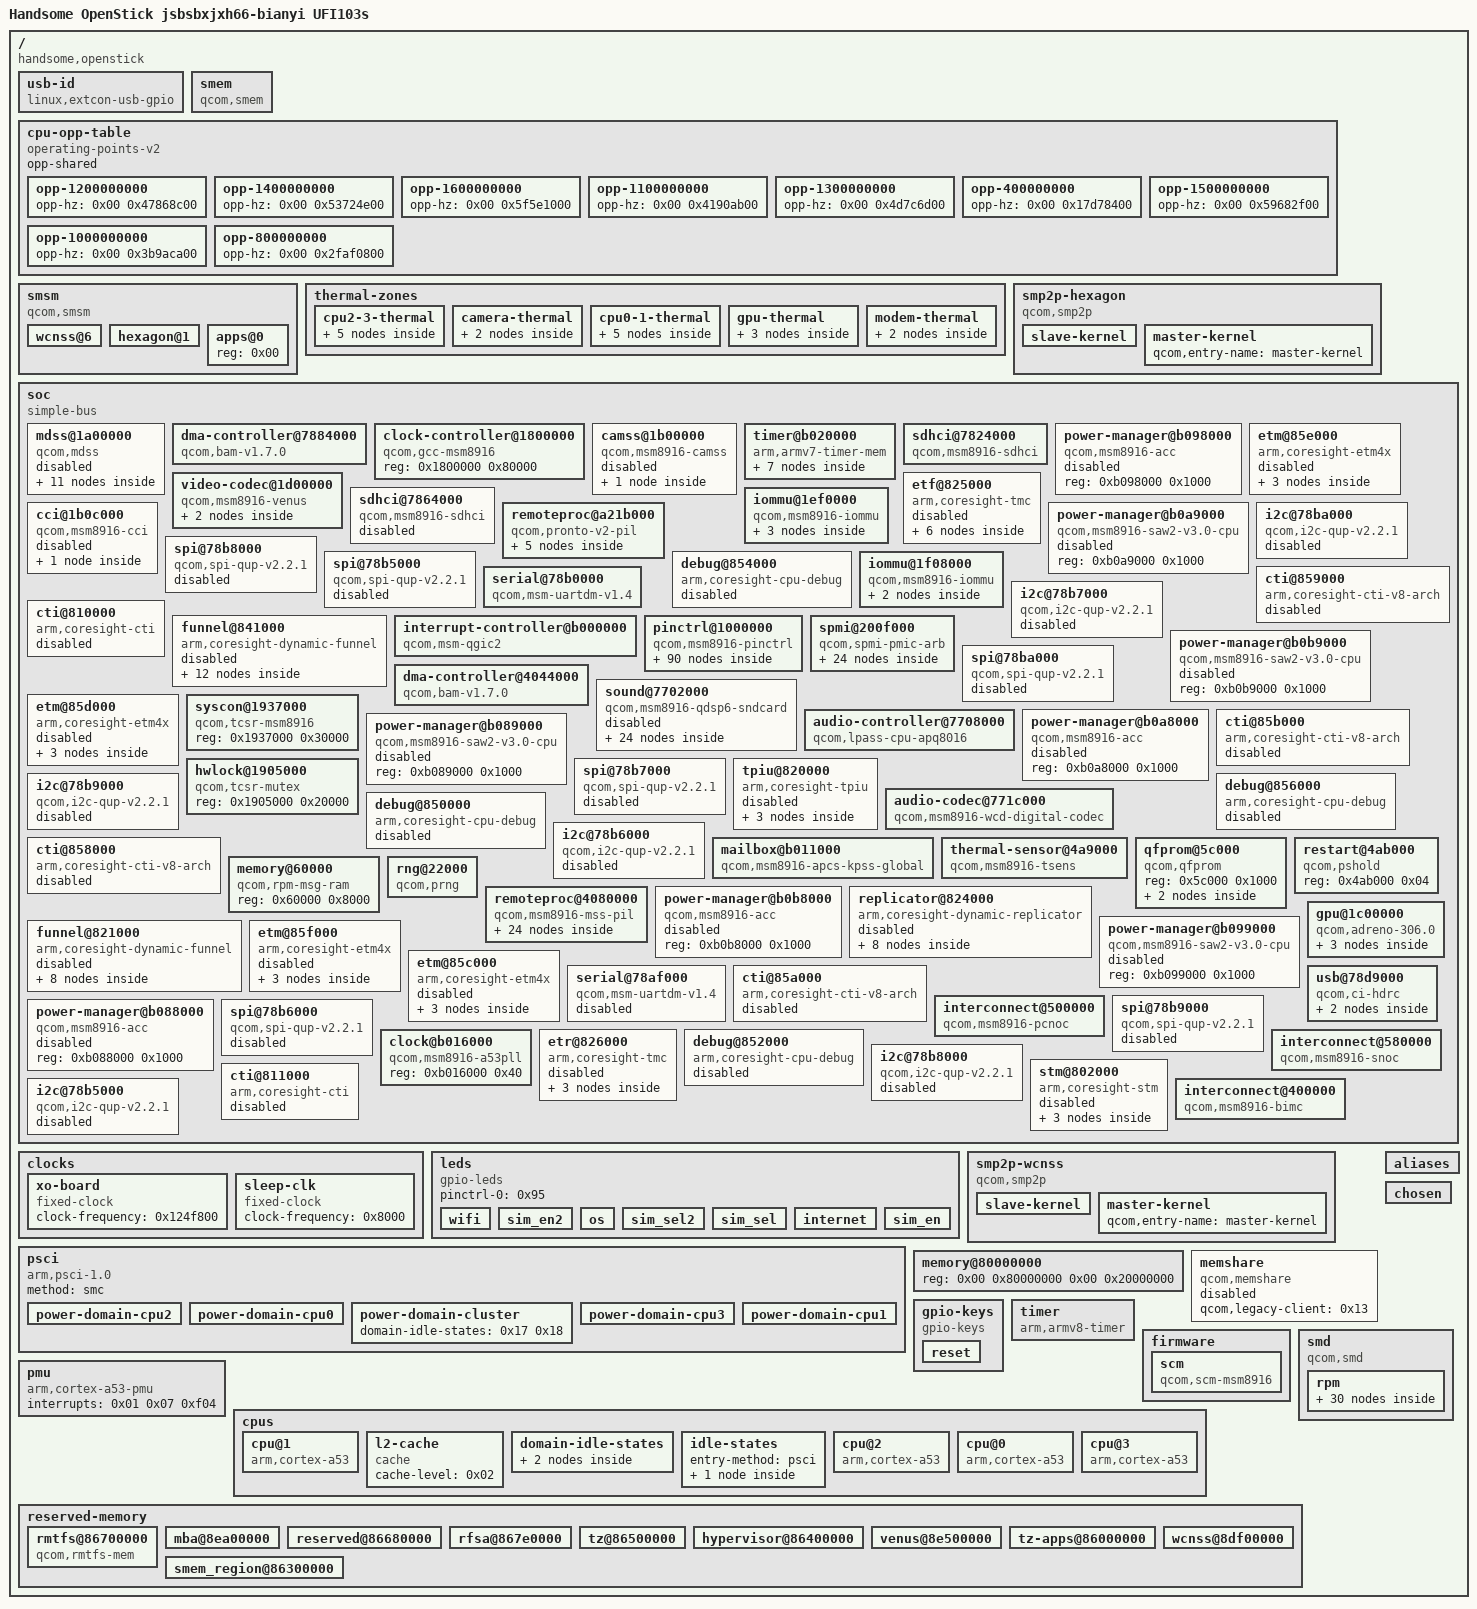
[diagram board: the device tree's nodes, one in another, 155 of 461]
/dts-v1/;

/ {
	#address-cells = <0x02>;
	model = "Handsome OpenStick  jsbsbxjxh66-bianyi UFI103s";
	#size-cells = <0x02>;
	interrupt-parent = <0x01>;
	compatible = "handsome,openstick\0qcom,msm8916";

	usb-id {
		pinctrl-names = "default";
		id-gpio = <0x3e 0x6e 0x00>;
		pinctrl-0 = <0x93>;
		compatible = "linux,extcon-usb-gpio";
		phandle = <0x87>;
	};

	smem {
		memory-region = <0x1c>;
		compatible = "qcom,smem";
		qcom,rpm-msg-ram = <0x1d>;
		hwlocks = <0x1e 0x03>;
	};

	cpu-opp-table {
		opp-shared;
		compatible = "operating-points-v2";
		phandle = <0x04>;

		opp-1200000000 {
			opp-hz = <0x00 0x47868c00>;
		};

		opp-1400000000 {
			opp-hz = <0x00 0x53724e00>;
		};

		opp-1600000000 {
			opp-hz = <0x00 0x5f5e1000>;
		};

		opp-1100000000 {
			opp-hz = <0x00 0x4190ab00>;
		};

		opp-1300000000 {
			opp-hz = <0x00 0x4d7c6d00>;
		};

		opp-400000000 {
			opp-hz = <0x00 0x17d78400>;
		};

		opp-1500000000 {
			opp-hz = <0x00 0x59682f00>;
		};

		opp-1000000000 {
			opp-hz = <0x00 0x3b9aca00>;
		};

		opp-800000000 {
			opp-hz = <0x00 0x2faf0800>;
		};
	};

	smsm {
		qcom,ipc-3 = <0x03 0x08 0x13>;
		#address-cells = <0x01>;
		qcom,ipc-1 = <0x03 0x08 0x0d>;
		#size-cells = <0x00>;
		compatible = "qcom,smsm";

		wcnss@6 {
			interrupts = <0x00 0x90 0x01>;
			#interrupt-cells = <0x02>;
			reg = <0x06>;
			interrupt-controller;
		};

		hexagon@1 {
			interrupts = <0x00 0x1a 0x01>;
			#interrupt-cells = <0x02>;
			reg = <0x01>;
			phandle = <0x55>;
			interrupt-controller;
		};

		apps@0 {
			#qcom,smem-state-cells = <0x01>;
			reg = <0x00>;
			phandle = <0x56>;
		};
	};

	thermal-zones {

		cpu2-3-thermal {
			polling-delay = <0x3e8>;
			polling-delay-passive = <0xfa>;
			thermal-sensors = <0x90 0x04>;

			trips {

				cpu_crit {
					temperature = <0x1adb0>;
					hysteresis = <0x7d0>;
					type = "critical";
				};

				trip-point0 {
					temperature = <0x124f8>;
					hysteresis = <0x7d0>;
					type = "passive";
					phandle = <0x92>;
				};
			};

			cooling-maps {

				map0 {
					trip = <0x92>;
					cooling-device = <0x32 0xffffffff 0xffffffff 0x33 0xffffffff 0xffffffff 0x34 0xffffffff 0xffffffff 0x35 0xffffffff 0xffffffff>;
				};
			};
		};

		camera-thermal {
			polling-delay = <0x3e8>;
			polling-delay-passive = <0xfa>;
			thermal-sensors = <0x90 0x01>;

			trips {

				trip-point0 {
					temperature = <0x124f8>;
					hysteresis = <0x7d0>;
					type = "hot";
				};
			};
		};

		cpu0-1-thermal {
			polling-delay = <0x3e8>;
			polling-delay-passive = <0xfa>;
			thermal-sensors = <0x90 0x05>;

			trips {

				cpu_crit {
					temperature = <0x1adb0>;
					hysteresis = <0x7d0>;
					type = "critical";
				};

				trip-point0 {
					temperature = <0x124f8>;
					hysteresis = <0x7d0>;
					type = "passive";
					phandle = <0x91>;
				};
			};

			cooling-maps {

				map0 {
					trip = <0x91>;
					cooling-device = <0x32 0xffffffff 0xffffffff 0x33 0xffffffff 0xffffffff 0x34 0xffffffff 0xffffffff 0x35 0xffffffff 0xffffffff>;
				};
			};
		};

		gpu-thermal {
			polling-delay = <0x3e8>;
			polling-delay-passive = <0xfa>;
			thermal-sensors = <0x90 0x02>;

			trips {

				gpu_crit {
					temperature = <0x17318>;
					hysteresis = <0x7d0>;
					type = "critical";
				};

				trip-point0 {
					temperature = <0x124f8>;
					hysteresis = <0x7d0>;
					type = "passive";
				};
			};
		};

		modem-thermal {
			polling-delay = <0x3e8>;
			polling-delay-passive = <0xfa>;
			thermal-sensors = <0x90 0x00>;

			trips {

				trip-point0 {
					temperature = <0x14c08>;
					hysteresis = <0x7d0>;
					type = "hot";
				};
			};
		};
	};

	smp2p-hexagon {
		qcom,local-pid = <0x00>;
		interrupts = <0x00 0x1b 0x01>;
		qcom,remote-pid = <0x01>;
		compatible = "qcom,smp2p";
		qcom,smem = <0x1b3 0x1ac>;
		qcom,ipc = <0x03 0x08 0x0e>;

		slave-kernel {
			qcom,entry-name = "slave-kernel";
			#interrupt-cells = <0x02>;
			phandle = <0x4f>;
			interrupt-controller;
		};

		master-kernel {
			qcom,entry-name = "master-kernel";
			#qcom,smem-state-cells = <0x01>;
			phandle = <0x51>;
		};
	};

	soc {
		#address-cells = <0x01>;
		#size-cells = <0x01>;
		compatible = "simple-bus";
		ranges = <0x00 0x00 0x00 0xffffffff>;

		mdss@1a00000 {
			power-domains = <0x11 0x02>;
			#address-cells = <0x01>;
			clock-names = "iface\0bus\0vsync";
			reg-names = "mdss_phys\0vbif_phys";
			interrupts = <0x00 0x48 0x04>;
			clocks = <0x11 0x6d 0x11 0x6e 0x11 0x73>;
			#size-cells = <0x01>;
			compatible = "qcom,mdss";
			ranges;
			#interrupt-cells = <0x01>;
			status = "disabled";
			reg = <0x1a00000 0x1000 0x1ac8000 0x3000>;
			phandle = <0x3f>;
			interrupt-controller;

			dsi-phy@1a98300 {
				clock-names = "iface\0ref";
				reg-names = "dsi_pll\0dsi_phy\0dsi_phy_regulator";
				clocks = <0x11 0x6d 0x46>;
				#clock-cells = <0x01>;
				#phy-cells = <0x00>;
				compatible = "qcom,dsi-phy-28nm-lp";
				vddio-supply = <0x44>;
				reg = <0x1a98300 0xd4 0x1a98500 0x280 0x1a98780 0x30>;
				phandle = <0x42>;
			};

			mdp@1a01000 {
				iommus = <0x40 0x04>;
				clock-names = "iface\0bus\0core\0vsync";
				reg-names = "mdp_phys";
				interrupts = <0x00>;
				clocks = <0x11 0x6d 0x11 0x6e 0x11 0x71 0x11 0x73>;
				interrupt-parent = <0x3f>;
				compatible = "qcom,mdp5";
				reg = <0x1a01000 0x89000>;

				ports {
					#address-cells = <0x01>;
					#size-cells = <0x00>;

					port@0 {
						reg = <0x00>;

						endpoint {
							remote-endpoint = <0x41>;
							phandle = <0x45>;
						};
					};
				};
			};

			dsi@1a98000 {
				#address-cells = <0x01>;
				phy-names = "dsi-phy";
				clock-names = "mdp_core\0iface\0bus\0byte\0pixel\0core";
				reg-names = "dsi_ctrl";
				assigned-clocks = <0x11 0x2b 0x11 0x2e>;
				assigned-clock-parents = <0x42 0x00 0x42 0x01>;
				vdda-supply = <0x43>;
				interrupts = <0x04>;
				clocks = <0x11 0x71 0x11 0x6d 0x11 0x6e 0x11 0x6f 0x11 0x72 0x11 0x70>;
				#size-cells = <0x00>;
				interrupt-parent = <0x3f>;
				compatible = "qcom,mdss-dsi-ctrl";
				vddio-supply = <0x44>;
				phys = <0x42>;
				reg = <0x1a98000 0x25c>;

				ports {
					#address-cells = <0x01>;
					#size-cells = <0x00>;

					port@0 {
						reg = <0x00>;

						endpoint {
							remote-endpoint = <0x45>;
							phandle = <0x41>;
						};
					};

					port@1 {
						reg = <0x01>;

						endpoint {
						};
					};
				};
			};
		};

		dma-controller@7884000 {
			clock-names = "bam_clk";
			interrupts = <0x00 0xee 0x04>;
			clocks = <0x11 0x36>;
			compatible = "qcom,bam-v1.7.0";
			status = "okay";
			reg = <0x7884000 0x23000>;
			phandle = <0x69>;
			qcom,ee = <0x00>;
			#dma-cells = <0x01>;
		};

		clock-controller@1800000 {
			#reset-cells = <0x01>;
			#clock-cells = <0x01>;
			#power-domain-cells = <0x01>;
			compatible = "qcom,gcc-msm8916";
			reg = <0x1800000 0x80000>;
			phandle = <0x11>;
		};

		camss@1b00000 {
			power-domains = <0x11 0x04>;
			iommus = <0x40 0x03>;
			clock-names = "top_ahb\0ispif_ahb\0csiphy0_timer\0csiphy1_timer\0csi0_ahb\0csi0\0csi0_phy\0csi0_pix\0csi0_rdi\0csi1_ahb\0csi1\0csi1_phy\0csi1_pix\0csi1_rdi\0ahb\0vfe0\0csi_vfe0\0vfe_ahb\0vfe_axi";
			reg-names = "csiphy0\0csiphy0_clk_mux\0csiphy1\0csiphy1_clk_mux\0csid0\0csid1\0ispif\0csi_clk_mux\0vfe0";
			vdda-supply = <0x43>;
			interrupts = <0x00 0x4e 0x01 0x00 0x4f 0x01 0x00 0x33 0x01 0x00 0x34 0x01 0x00 0x37 0x01 0x00 0x39 0x01>;
			clocks = <0x11 0x60 0x11 0x56 0x11 0x5d 0x11 0x5e 0x11 0x49 0x11 0x4a 0x11 0x4b 0x11 0x4c 0x11 0x4d 0x11 0x4e 0x11 0x4f 0x11 0x50 0x11 0x51 0x11 0x52 0x11 0x5f 0x11 0x63 0x11 0x53 0x11 0x64 0x11 0x65>;
			compatible = "qcom,msm8916-camss";
			status = "disabled";
			interrupt-names = "csiphy0\0csiphy1\0csid0\0csid1\0ispif\0vfe0";
			reg = <0x1b0ac00 0x200 0x1b00030 0x04 0x1b0b000 0x200 0x1b00038 0x04 0x1b08000 0x100 0x1b08400 0x100 0x1b0a000 0x500 0x1b00020 0x10 0x1b10000 0x1000>;

			ports {
				#address-cells = <0x01>;
				#size-cells = <0x00>;
			};
		};

		timer@b020000 {
			#address-cells = <0x01>;
			#size-cells = <0x01>;
			clock-frequency = <0x124f800>;
			compatible = "arm,armv7-timer-mem";
			ranges;
			reg = <0xb020000 0x1000>;

			frame@b028000 {
				interrupts = <0x00 0x0e 0x04>;
				frame-number = <0x06>;
				status = "disabled";
				reg = <0xb028000 0x1000>;
			};

			frame@b025000 {
				interrupts = <0x00 0x0b 0x04>;
				frame-number = <0x03>;
				status = "disabled";
				reg = <0xb025000 0x1000>;
			};

			frame@b027000 {
				interrupts = <0x00 0x0d 0x04>;
				frame-number = <0x05>;
				status = "disabled";
				reg = <0xb027000 0x1000>;
			};

			frame@b024000 {
				interrupts = <0x00 0x0a 0x04>;
				frame-number = <0x02>;
				status = "disabled";
				reg = <0xb024000 0x1000>;
			};

			frame@b021000 {
				interrupts = <0x00 0x08 0x04 0x00 0x07 0x04>;
				frame-number = <0x00>;
				reg = <0xb021000 0x1000 0xb022000 0x1000>;
			};

			frame@b026000 {
				interrupts = <0x00 0x0c 0x04>;
				frame-number = <0x04>;
				status = "disabled";
				reg = <0xb026000 0x1000>;
			};

			frame@b023000 {
				interrupts = <0x00 0x09 0x04>;
				frame-number = <0x01>;
				status = "disabled";
				reg = <0xb023000 0x1000>;
			};
		};

		sdhci@7824000 {
			pinctrl-names = "default\0sleep";
			pinctrl-0 = <0x61 0x62 0x63>;
			clock-names = "core\0iface\0xo";
			vqmmc-supply = <0x4d>;
			reg-names = "hc_mem\0core_mem";
			bus-width = <0x08>;
			non-removable;
			interrupts = <0x00 0x7b 0x04 0x00 0x8a 0x04>;
			clocks = <0x11 0x7b 0x11 0x7a 0x46>;
			vmmc-supply = <0x60>;
			mmc-ddr-1_8v;
			compatible = "qcom,msm8916-sdhci\0qcom,sdhci-msm-v4";
			pinctrl-1 = <0x64 0x65 0x66>;
			status = "okay";
			interrupt-names = "hc_irq\0pwr_irq";
			reg = <0x7824900 0x11c 0x7824000 0x800>;
		};

		power-manager@b098000 {
			compatible = "qcom,msm8916-acc";
			status = "reserved";
			reg = <0xb098000 0x1000>;
			phandle = <0x09>;
		};

		etm@85e000 {
			clock-names = "apb_pclk\0atclk";
			clocks = <0x1f 0x08 0x1f 0x09>;
			arm,coresight-loses-context-with-cpu;
			cpu = <0x34>;
			compatible = "arm,coresight-etm4x\0arm,primecell";
			status = "disabled";
			reg = <0x85e000 0x1000>;
			phandle = <0x38>;

			out-ports {

				port {

					endpoint {
						remote-endpoint = <0x3c>;
						phandle = <0x2f>;
					};
				};
			};
		};

		video-codec@1d00000 {
			power-domains = <0x11 0x01>;
			iommus = <0x40 0x05>;
			clock-names = "core\0iface\0bus";
			memory-region = <0x4a>;
			interrupts = <0x00 0x2c 0x04>;
			clocks = <0x11 0x89 0x11 0x87 0x11 0x88>;
			compatible = "qcom,msm8916-venus";
			status = "okay";
			reg = <0x1d00000 0xff000>;

			video-encoder {
				compatible = "venus-encoder";
			};

			video-decoder {
				compatible = "venus-decoder";
			};
		};

		etf@825000 {
			clock-names = "apb_pclk\0atclk";
			clocks = <0x1f 0x08 0x1f 0x09>;
			compatible = "arm,coresight-tmc\0arm,primecell";
			status = "disabled";
			reg = <0x825000 0x1000>;

			in-ports {

				port {

					endpoint {
						remote-endpoint = <0x2a>;
						phandle = <0x26>;
					};
				};
			};

			out-ports {

				port {

					endpoint {
						remote-endpoint = <0x2b>;
						phandle = <0x29>;
					};
				};
			};
		};

		sdhci@7864000 {
			clock-names = "core\0iface\0xo";
			vqmmc-supply = <0x68>;
			reg-names = "hc_mem\0core_mem";
			bus-width = <0x04>;
			interrupts = <0x00 0x7d 0x04 0x00 0xdd 0x04>;
			clocks = <0x11 0x7d 0x11 0x7c 0x46>;
			vmmc-supply = <0x67>;
			compatible = "qcom,msm8916-sdhci\0qcom,sdhci-msm-v4";
			status = "disabled";
			interrupt-names = "hc_irq\0pwr_irq";
			reg = <0x7864900 0x11c 0x7864000 0x800>;
		};

		remoteproc@a21b000 {
			power-domains = <0x50 0x00 0x50 0x03>;
			pinctrl-names = "default";
			vddpx-supply = <0x53>;
			pinctrl-0 = <0x8c>;
			reg-names = "ccu\0dxe\0pmu";
			power-domain-names = "cx\0mx";
			memory-region = <0x89>;
			interrupts-extended = <0x01 0x00 0x95 0x01 0x8a 0x00 0x01 0x8a 0x01 0x01 0x8a 0x02 0x01 0x8a 0x03 0x01>;
			compatible = "qcom,pronto-v2-pil\0qcom,pronto";
			status = "okay";
			interrupt-names = "wdog\0fatal\0ready\0handover\0stop-ack";
			reg = <0xa204000 0x2000 0xa202000 0x1000 0xa21b000 0x3000>;
			phandle = <0x8e>;
			qcom,state = <0x8b 0x00>;
			qcom,state-names = "stop";

			iris {
				clock-names = "xo";
				clocks = <0x1f 0x10>;
				vddpa-supply = <0x8d>;
				compatible = "qcom,wcn3620";
				vddxo-supply = <0x53>;
				vddrfa-supply = <0x1a>;
				vdddig-supply = <0x4d>;
			};

			smd-edge {
				interrupts = <0x00 0x8e 0x01>;
				qcom,smd-edge = <0x06>;
				label = "pronto";
				qcom,remote-pid = <0x04>;
				qcom,ipc = <0x03 0x08 0x11>;

				wcnss {
					compatible = "qcom,wcnss";
					qcom,smd-channels = "WCNSS_CTRL";
					qcom,mmio = <0x8e>;

					bt {
						local-bd-address = [b0 04 24 07 00 02];
						local-mac-address = [02 00 07 24 04 b0];
						compatible = "qcom,wcnss-bt";
					};

					wifi {
						qcom,smem-state-names = "tx-enable\0tx-rings-empty";
						local-mac-address = [02 00 07 24 04 b1];
						interrupts = <0x00 0x91 0x04 0x00 0x92 0x04>;
						compatible = "qcom,wcnss-wlan";
						interrupt-names = "tx\0rx";
						qcom,smem-states = <0x56 0x0a 0x56 0x09>;
					};
				};
			};
		};

		iommu@1ef0000 {
			qcom,iommu-secure-id = <0x11>;
			#address-cells = <0x01>;
			clock-names = "iface\0bus";
			clocks = <0x11 0x81 0x11 0x8b>;
			#size-cells = <0x01>;
			#iommu-cells = <0x01>;
			compatible = "qcom,msm8916-iommu\0qcom,msm-iommu-v1";
			ranges = <0x00 0x1e20000 0x40000>;
			reg = <0x1ef0000 0x3000>;
			phandle = <0x40>;

			iommu-ctx@3000 {
				interrupts = <0x00 0x46 0x04>;
				compatible = "qcom,msm-iommu-v1-sec";
				reg = <0x3000 0x1000>;
			};

			iommu-ctx@5000 {
				interrupts = <0x00 0x46 0x04>;
				compatible = "qcom,msm-iommu-v1-sec";
				reg = <0x5000 0x1000>;
			};

			iommu-ctx@4000 {
				interrupts = <0x00 0x46 0x04>;
				compatible = "qcom,msm-iommu-v1-ns";
				reg = <0x4000 0x1000>;
			};
		};

		cci@1b0c000 {
			pinctrl-names = "default";
			#address-cells = <0x01>;
			pinctrl-0 = <0x47>;
			clock-names = "camss_top_ahb\0cci_ahb\0cci\0camss_ahb";
			assigned-clocks = <0x11 0x47 0x11 0x48>;
			assigned-clock-rates = <0x4c4b400 0x124f800>;
			interrupts = <0x00 0x32 0x01>;
			clocks = <0x11 0x60 0x11 0x47 0x11 0x48 0x11 0x5f>;
			#size-cells = <0x00>;
			compatible = "qcom,msm8916-cci";
			status = "disabled";
			reg = <0x1b0c000 0x1000>;

			i2c-bus@0 {
				#address-cells = <0x01>;
				#size-cells = <0x00>;
				clock-frequency = <0x61a80>;
				reg = <0x00>;
			};
		};

		power-manager@b0a9000 {
			compatible = "qcom,msm8916-saw2-v3.0-cpu\0qcom,saw2";
			status = "reserved";
			reg = <0xb0a9000 0x1000>;
			phandle = <0x0d>;
		};

		i2c@78ba000 {
			pinctrl-names = "default\0sleep";
			#address-cells = <0x01>;
			pinctrl-0 = <0x82>;
			clock-names = "iface\0core";
			interrupts = <0x00 0x64 0x04>;
			clocks = <0x11 0x36 0x11 0x42>;
			#size-cells = <0x00>;
			compatible = "qcom,i2c-qup-v2.2.1";
			pinctrl-1 = <0x83>;
			status = "disabled";
			reg = <0x78ba000 0x500>;
		};

		spi@78b8000 {
			pinctrl-names = "default\0sleep";
			#address-cells = <0x01>;
			pinctrl-0 = <0x7c>;
			clock-names = "core\0iface";
			interrupts = <0x00 0x62 0x04>;
			clocks = <0x11 0x3f 0x11 0x36>;
			#size-cells = <0x00>;
			dma-names = "rx\0tx";
			compatible = "qcom,spi-qup-v2.2.1";
			pinctrl-1 = <0x7d>;
			status = "disabled";
			reg = <0x78b8000 0x500>;
			dmas = <0x69 0x0b 0x69 0x0a>;
		};

		spi@78b5000 {
			pinctrl-names = "default\0sleep";
			#address-cells = <0x01>;
			pinctrl-0 = <0x70>;
			clock-names = "core\0iface";
			interrupts = <0x00 0x5f 0x04>;
			clocks = <0x11 0x39 0x11 0x36>;
			#size-cells = <0x00>;
			dma-names = "rx\0tx";
			compatible = "qcom,spi-qup-v2.2.1";
			pinctrl-1 = <0x71>;
			status = "disabled";
			reg = <0x78b5000 0x500>;
			dmas = <0x69 0x05 0x69 0x04>;
		};

		debug@854000 {
			clock-names = "apb_pclk";
			clocks = <0x1f 0x08>;
			cpu = <0x34>;
			compatible = "arm,coresight-cpu-debug\0arm,primecell";
			status = "disabled";
			reg = <0x854000 0x1000>;
		};

		cti@859000 {
			clock-names = "apb_pclk";
			clocks = <0x1f 0x08>;
			cpu = <0x33>;
			arm,cs-dev-assoc = <0x37>;
			compatible = "arm,coresight-cti-v8-arch\0arm,coresight-cti\0arm,primecell";
			status = "disabled";
			reg = <0x859000 0x1000>;
		};

		iommu@1f08000 {
			qcom,iommu-secure-id = <0x12>;
			#address-cells = <0x01>;
			clock-names = "iface\0bus";
			clocks = <0x11 0x81 0x11 0x8c>;
			#size-cells = <0x01>;
			#iommu-cells = <0x01>;
			compatible = "qcom,msm8916-iommu\0qcom,msm-iommu-v1";
			ranges = <0x00 0x1f08000 0x10000>;
			phandle = <0x49>;

			iommu-ctx@2000 {
				interrupts = <0x00 0xf2 0x04>;
				compatible = "qcom,msm-iommu-v1-ns";
				reg = <0x2000 0x1000>;
			};

			iommu-ctx@1000 {
				interrupts = <0x00 0xf1 0x04>;
				compatible = "qcom,msm-iommu-v1-ns";
				reg = <0x1000 0x1000>;
			};
		};

		serial@78b0000 {
			pinctrl-names = "default\0sleep";
			pinctrl-0 = <0x6c>;
			clock-names = "core\0iface";
			interrupts = <0x00 0x6c 0x04>;
			clocks = <0x11 0x45 0x11 0x36>;
			dma-names = "rx\0tx";
			compatible = "qcom,msm-uartdm-v1.4\0qcom,msm-uartdm";
			pinctrl-1 = <0x6d>;
			status = "okay";
			reg = <0x78b0000 0x200>;
			dmas = <0x69 0x03 0x69 0x02>;
		};

		i2c@78b7000 {
			pinctrl-names = "default\0sleep";
			#address-cells = <0x01>;
			pinctrl-0 = <0x76>;
			clock-names = "iface\0core";
			interrupts = <0x00 0x61 0x04>;
			clocks = <0x11 0x36 0x11 0x3c>;
			#size-cells = <0x00>;
			compatible = "qcom,i2c-qup-v2.2.1";
			pinctrl-1 = <0x77>;
			status = "disabled";
			reg = <0x78b7000 0x500>;
		};

		cti@810000 {
			clock-names = "apb_pclk";
			clocks = <0x1f 0x08>;
			compatible = "arm,coresight-cti\0arm,primecell";
			status = "disabled";
			reg = <0x810000 0x1000>;
		};

		funnel@841000 {
			clock-names = "apb_pclk\0atclk";
			clocks = <0x1f 0x08 0x1f 0x09>;
			compatible = "arm,coresight-dynamic-funnel\0arm,primecell";
			status = "disabled";
			reg = <0x841000 0x1000>;

			in-ports {
				#address-cells = <0x01>;
				#size-cells = <0x00>;

				port@0 {
					reg = <0x00>;

					endpoint {
						remote-endpoint = <0x2d>;
						phandle = <0x3a>;
					};
				};

				port@3 {
					reg = <0x03>;

					endpoint {
						remote-endpoint = <0x30>;
						phandle = <0x3d>;
					};
				};

				port@1 {
					reg = <0x01>;

					endpoint {
						remote-endpoint = <0x2e>;
						phandle = <0x3b>;
					};
				};

				port@2 {
					reg = <0x02>;

					endpoint {
						remote-endpoint = <0x2f>;
						phandle = <0x3c>;
					};
				};
			};

			out-ports {

				port {

					endpoint {
						remote-endpoint = <0x31>;
						phandle = <0x24>;
					};
				};
			};
		};

		interrupt-controller@b000000 {
			interrupts = <0x01 0x00 0xf04>;
			compatible = "qcom,msm-qgic2";
			#interrupt-cells = <0x03>;
			reg = <0xb000000 0x1000 0xb002000 0x2000 0xb001000 0x1000 0xb004000 0x2000>;
			phandle = <0x01>;
			interrupt-controller;
		};

		pinctrl@1000000 {
			gpio-controller;
			interrupts = <0x00 0xd0 0x04>;
			compatible = "qcom,msm8916-pinctrl";
			#interrupt-cells = <0x02>;
			reg = <0x1000000 0x300000>;
			phandle = <0x3e>;
			#gpio-cells = <0x02>;
			gpio-ranges = <0x3e 0x00 0x00 0x7a>;
			interrupt-controller;

			pmx-sdc1-clk {

				clk-on {
					pins = "sdc1_clk";
					drive-strength = <0x10>;
					bias-disable;
					phandle = <0x61>;
				};

				clk-off {
					pins = "sdc1_clk";
					drive-strength = <0x02>;
					bias-disable;
					phandle = <0x64>;
				};
			};

			spi6-default {
				function = "blsp_spi6";
				pins = "gpio20\0gpio21\0gpio23";
				drive-strength = <0x0c>;
				bias-disable;
				phandle = <0x84>;

				cs {
					function = "gpio";
					pins = "gpio22";
					drive-strength = <0x10>;
					bias-disable;
					output-high;
				};
			};

			ext-pri-ws-line {

				ext-pa-on {
					function = "pri_mi2s_ws";
					pins = "gpio110";
					drive-strength = <0x08>;
					bias-disable;
				};

				ext-pa-off {
					function = "pri_mi2s_ws";
					pins = "gpio110";
					drive-strength = <0x02>;
					bias-disable;
				};
			};

			blsp1-uart2-sleep {
				function = "gpio";
				pins = "gpio4\0gpio5";
				drive-strength = <0x02>;
				bias-pull-down;
				phandle = <0x6d>;
			};

			i2c4-default {
				function = "blsp_i2c4";
				pins = "gpio14\0gpio15";
				drive-strength = <0x02>;
				bias-disable;
				phandle = <0x7a>;
			};

			cdc-dmic-lines {

				dmic-lines-off {

					clk {
						function = "dmic0_clk";
						pins = "gpio0";
						drive-strength = <0x02>;
						bias-disable;
					};

					data {
						function = "dmic0_data";
						pins = "gpio1";
						drive-strength = <0x02>;
						bias-disable;
					};
				};

				dmic-lines-on {

					clk {
						function = "dmic0_clk";
						pins = "gpio0";
						drive-strength = <0x08>;
					};

					data {
						function = "dmic0_data";
						pins = "gpio1";
						drive-strength = <0x08>;
					};
				};
			};

			ext-mclk-tlmm-lines {

				mclk-lines-on {
					function = "pri_mi2s";
					pins = "gpio116";
					drive-strength = <0x08>;
					bias-disable;
				};

				mclk-lines-off {
					function = "pri_mi2s";
					pins = "gpio116";
					drive-strength = <0x02>;
					bias-disable;
				};
			};

			pmx-sdc2-cmd {

				cmd-off {
					pins = "sdc2_cmd";
					drive-strength = <0x02>;
					bias-pull-up;
				};

				cmd-on {
					pins = "sdc2_cmd";
					drive-strength = <0x0a>;
					bias-pull-up;
				};
			};

			usb-id-default {
				function = "gpio";
				pins = "gpio110";
				drive-strength = <0x08>;
				phandle = <0x93>;
				bias-pull-up;
				input-enable;
			};

			i2c2-sleep {
				function = "gpio";
				pins = "gpio6\0gpio7";
				drive-strength = <0x02>;
				bias-disable;
				phandle = <0x73>;
			};

			i2c6-default {
				function = "blsp_i2c6";
				pins = "gpio22\0gpio23";
				drive-strength = <0x02>;
				bias-disable;
				phandle = <0x82>;
			};

			spi1-default {
				function = "blsp_spi1";
				pins = "gpio0\0gpio1\0gpio3";
				drive-strength = <0x0c>;
				bias-disable;
				phandle = <0x70>;

				cs {
					function = "gpio";
					pins = "gpio2";
					drive-strength = <0x10>;
					bias-disable;
					output-high;
				};
			};

			i2c6-sleep {
				function = "gpio";
				pins = "gpio22\0gpio23";
				drive-strength = <0x02>;
				bias-disable;
				phandle = <0x83>;
			};

			blsp1-uart1-default {
				function = "blsp_uart1";
				pins = "gpio0\0gpio1\0gpio2\0gpio3";
				drive-strength = <0x10>;
				bias-disable;
				phandle = <0x6a>;
			};

			spi4-sleep {
				function = "gpio";
				pins = "gpio12\0gpio13\0gpio14\0gpio15";
				drive-strength = <0x02>;
				bias-pull-down;
				phandle = <0x7d>;
			};

			pmx-sdc2-clk {

				clk-on {
					pins = "sdc2_clk";
					drive-strength = <0x10>;
					bias-disable;
				};

				clk-off {
					pins = "sdc2_clk";
					drive-strength = <0x02>;
					bias-disable;
				};
			};

			camera-rear-default {

				rst {
					function = "gpio";
					pins = "gpio35";
					drive-strength = <0x10>;
					bias-disable;
				};

				pwdn {
					function = "gpio";
					pins = "gpio34";
					drive-strength = <0x10>;
					bias-disable;
				};

				mclk0 {
					function = "cam_mclk0";
					pins = "gpio26";
					drive-strength = <0x10>;
					bias-disable;
				};
			};

			spi3-default {
				function = "blsp_spi3";
				pins = "gpio8\0gpio9\0gpio11";
				drive-strength = <0x0c>;
				bias-disable;
				phandle = <0x78>;

				cs {
					function = "gpio";
					pins = "gpio10";
					drive-strength = <0x10>;
					bias-disable;
					output-high;
				};
			};

			i2c1-default {
				function = "blsp_i2c1";
				pins = "gpio2\0gpio3";
				drive-strength = <0x02>;
				bias-disable;
				phandle = <0x6e>;
			};

			wcnss-active {
				function = "wcss_wlan";
				pins = "gpio40\0gpio41\0gpio42\0gpio43\0gpio44";
				drive-strength = <0x06>;
				phandle = <0x8c>;
				bias-pull-up;
			};

			i2c3-sleep {
				function = "gpio";
				pins = "gpio10\0gpio11";
				drive-strength = <0x02>;
				bias-disable;
				phandle = <0x77>;
			};

			spi1-sleep {
				function = "gpio";
				pins = "gpio0\0gpio1\0gpio2\0gpio3";
				drive-strength = <0x02>;
				bias-pull-down;
				phandle = <0x71>;
			};

			spi5-default {
				function = "blsp_spi5";
				pins = "gpio16\0gpio17\0gpio19";
				drive-strength = <0x0c>;
				bias-disable;
				phandle = <0x80>;

				cs {
					function = "gpio";
					pins = "gpio18";
					drive-strength = <0x10>;
					bias-disable;
					output-high;
				};
			};

			cdc-pdm-lines {

				pdm-lines-on {
					function = "cdc_pdm0";
					pins = "gpio63\0gpio64\0gpio65\0gpio66\0gpio67\0gpio68";
					drive-strength = <0x08>;
					bias-disable;
					phandle = <0x58>;
				};

				pdm-lines-off {
					function = "cdc_pdm0";
					pins = "gpio63\0gpio64\0gpio65\0gpio66\0gpio67\0gpio68";
					drive-strength = <0x02>;
					bias-pull-down;
					phandle = <0x59>;
				};
			};

			pmx-sdc2-cd-pin {

				cd-off {
					function = "gpio";
					pins = "gpio38";
					drive-strength = <0x02>;
					bias-disable;
				};

				cd-on {
					function = "gpio";
					pins = "gpio38";
					drive-strength = <0x02>;
					bias-pull-up;
				};
			};

			i2c3-default {
				function = "blsp_i2c3";
				pins = "gpio10\0gpio11";
				drive-strength = <0x02>;
				bias-disable;
				phandle = <0x76>;
			};

			ext-pri-tlmm-lines {

				ext-pa-on {
					function = "pri_mi2s";
					pins = "gpio113\0gpio114\0gpio115\0gpio116";
					drive-strength = <0x08>;
					bias-disable;
				};

				ext-pa-off {
					function = "pri_mi2s";
					pins = "gpio113\0gpio114\0gpio115\0gpio116";
					drive-strength = <0x02>;
					bias-disable;
				};
			};

			pmx-sdc2-data {

				data-on {
					pins = "sdc2_data";
					drive-strength = <0x0a>;
					bias-pull-up;
				};

				data-off {
					pins = "sdc2_data";
					drive-strength = <0x02>;
					bias-pull-up;
				};
			};

			gpio_keys_default {
				function = "gpio";
				pins = "gpio37";
				drive-strength = <0x08>;
				phandle = <0x94>;
				bias-pull-up;
				input-enable;
			};

			msmgpio-leds {
				function = "gpio";
				bias-disabled;
				pins = "gpio0\0gpio1\0gpio2\0gpio3\0gpio20\0gpio21\0gpio22";
				phandle = <0x95>;
			};

			spi5-sleep {
				function = "gpio";
				pins = "gpio16\0gpio17\0gpio18\0gpio19";
				drive-strength = <0x02>;
				bias-pull-down;
				phandle = <0x81>;
			};

			cci0-default {
				function = "cci_i2c";
				pins = "gpio29\0gpio30";
				drive-strength = <0x10>;
				bias-disable;
				phandle = <0x47>;
			};

			i2c5-default {
				function = "blsp_i2c5";
				pins = "gpio18\0gpio19";
				drive-strength = <0x02>;
				bias-disable;
				phandle = <0x7e>;
			};

			pmx-sdc1-data {

				data-on {
					pins = "sdc1_data";
					drive-strength = <0x0a>;
					phandle = <0x63>;
					bias-pull-up;
				};

				data-off {
					pins = "sdc1_data";
					drive-strength = <0x02>;
					phandle = <0x66>;
					bias-pull-up;
				};
			};

			i2c4-sleep {
				function = "gpio";
				pins = "gpio14\0gpio15";
				drive-strength = <0x02>;
				bias-disable;
				phandle = <0x7b>;
			};

			spi2-sleep {
				function = "gpio";
				pins = "gpio4\0gpio5\0gpio6\0gpio7";
				drive-strength = <0x02>;
				bias-pull-down;
				phandle = <0x75>;
			};

			blsp1-uart1-sleep {
				function = "gpio";
				pins = "gpio0\0gpio1\0gpio2\0gpio3";
				drive-strength = <0x02>;
				bias-pull-down;
				phandle = <0x6b>;
			};

			spi2-default {
				function = "blsp_spi2";
				pins = "gpio4\0gpio5\0gpio7";
				drive-strength = <0x0c>;
				bias-disable;
				phandle = <0x74>;

				cs {
					function = "gpio";
					pins = "gpio6";
					drive-strength = <0x10>;
					bias-disable;
					output-high;
				};
			};

			blsp1-uart2-default {
				function = "blsp_uart2";
				pins = "gpio4\0gpio5";
				drive-strength = <0x10>;
				bias-disable;
				phandle = <0x6c>;
			};

			spi6-sleep {
				function = "gpio";
				pins = "gpio20\0gpio21\0gpio22\0gpio23";
				drive-strength = <0x02>;
				bias-pull-down;
				phandle = <0x85>;
			};

			pmx-sdc1-cmd {

				cmd-off {
					pins = "sdc1_cmd";
					drive-strength = <0x02>;
					phandle = <0x65>;
					bias-pull-up;
				};

				cmd-on {
					pins = "sdc1_cmd";
					drive-strength = <0x0a>;
					phandle = <0x62>;
					bias-pull-up;
				};
			};

			i2c1-sleep {
				function = "gpio";
				pins = "gpio2\0gpio3";
				drive-strength = <0x02>;
				bias-disable;
				phandle = <0x6f>;
			};

			camera-front-default {

				rst {
					function = "gpio";
					pins = "gpio28";
					drive-strength = <0x10>;
					bias-disable;
				};

				pwdn {
					function = "gpio";
					pins = "gpio33";
					drive-strength = <0x10>;
					bias-disable;
				};

				mclk1 {
					function = "cam_mclk1";
					pins = "gpio27";
					drive-strength = <0x10>;
					bias-disable;
				};
			};

			spi4-default {
				function = "blsp_spi4";
				pins = "gpio12\0gpio13\0gpio15";
				drive-strength = <0x0c>;
				bias-disable;
				phandle = <0x7c>;

				cs {
					function = "gpio";
					pins = "gpio14";
					drive-strength = <0x10>;
					bias-disable;
					output-high;
				};
			};

			ext-sec-tlmm-lines {

				tlmm-lines-off {
					function = "sec_mi2s";
					pins = "gpio112\0gpio117\0gpio118\0gpio119";
					drive-strength = <0x02>;
					bias-disable;
				};

				tlmm-lines-on {
					function = "sec_mi2s";
					pins = "gpio112\0gpio117\0gpio118\0gpio119";
					drive-strength = <0x08>;
					bias-disable;
				};
			};

			i2c2-default {
				function = "blsp_i2c2";
				pins = "gpio6\0gpio7";
				drive-strength = <0x02>;
				bias-disable;
				phandle = <0x72>;
			};

			i2c5-sleep {
				function = "gpio";
				pins = "gpio18\0gpio19";
				drive-strength = <0x02>;
				bias-disable;
				phandle = <0x7f>;
			};

			spi3-sleep {
				function = "gpio";
				pins = "gpio8\0gpio9\0gpio10\0gpio11";
				drive-strength = <0x02>;
				bias-pull-down;
				phandle = <0x79>;
			};
		};

		power-manager@b0b9000 {
			compatible = "qcom,msm8916-saw2-v3.0-cpu\0qcom,saw2";
			status = "reserved";
			reg = <0xb0b9000 0x1000>;
			phandle = <0x10>;
		};

		spmi@200f000 {
			#address-cells = <0x02>;
			reg-names = "core\0chnls\0obsrvr\0intr\0cnfg";
			qcom,channel = <0x00>;
			interrupts = <0x00 0xbe 0x04>;
			#size-cells = <0x00>;
			compatible = "qcom,spmi-pmic-arb";
			#interrupt-cells = <0x04>;
			interrupt-names = "periph_irq";
			reg = <0x200f000 0x1000 0x2400000 0x400000 0x2c00000 0x400000 0x3800000 0x200000 0x200a000 0x2100>;
			phandle = <0x4c>;
			qcom,ee = <0x00>;
			interrupt-controller;

			pmic@0 {
				#address-cells = <0x01>;
				#size-cells = <0x00>;
				compatible = "qcom,pm8916\0qcom,spmi-pmic";
				reg = <0x00 0x00>;

				gpios@c000 {
					gpio-controller;
					interrupts = <0x00 0xc0 0x00 0x00 0x00 0xc1 0x00 0x00 0x00 0xc2 0x00 0x00 0x00 0xc3 0x00 0x00>;
					compatible = "qcom,pm8916-gpio";
					reg = <0xc000>;
					#gpio-cells = <0x02>;
				};

				temp-alarm@2400 {
					interrupts = <0x00 0x24 0x00 0x01>;
					io-channels = <0x4b 0x08>;
					#thermal-sensor-cells = <0x00>;
					compatible = "qcom,spmi-temp-alarm";
					reg = <0x2400>;
					io-channel-names = "thermal";
				};

				extcon@1300 {
					interrupts = <0x00 0x13 0x01 0x03>;
					compatible = "qcom,pm8941-misc";
					status = "disabled";
					interrupt-names = "usb_vbus";
					reg = <0x1300>;
				};

				pon@800 {
					mode-bootloader = <0x02>;
					mode-recovery = <0x01>;
					compatible = "qcom,pm8916-pon";
					reg = <0x800>;

					resin {
						debounce = <0x3d09>;
						interrupts = <0x00 0x08 0x01 0x03>;
						compatible = "qcom,pm8941-resin";
						status = "disabled";
						bias-pull-up;
					};

					pwrkey {
						debounce = <0x3d09>;
						interrupts = <0x00 0x08 0x00 0x03>;
						compatible = "qcom,pm8941-pwrkey";
						linux,code = <0x74>;
						bias-pull-up;
					};

					watchdog {
						interrupts = <0x00 0x08 0x06 0x01>;
						timeout-sec = <0x3c>;
						compatible = "qcom,pm8916-wdt";
					};
				};

				vm-bms@4000 {
					interrupts = <0x00 0x40 0x04 0x01>;
					compatible = "qcom,pm8916-bms-vm";
					status = "disabled";
					reg = <0x4000>;
				};

				mpps@a000 {
					gpio-controller;
					interrupts = <0x00 0xa0 0x00 0x00 0x00 0xa1 0x00 0x00 0x00 0xa2 0x00 0x00 0x00 0xa3 0x00 0x00>;
					compatible = "qcom,pm8916-mpp";
					reg = <0xa000>;
					#gpio-cells = <0x02>;
				};

				charger@1000 {
					interrupts = <0x00 0x13 0x01 0x03>;
					compatible = "qcom,pm8916-lbc";
					status = "disabled";
					reg = <0x1000 0x1200 0x1300 0x1600>;
				};

				adc@3100 {
					#address-cells = <0x01>;
					interrupts = <0x00 0x31 0x00 0x01>;
					#io-channel-cells = <0x01>;
					#size-cells = <0x00>;
					compatible = "qcom,spmi-vadc";
					reg = <0x3100>;
					phandle = <0x4b>;

					adc-chan@7 {
						qcom,pre-scaling = <0x01 0x03>;
						reg = <0x07>;
					};

					adc-chan@e {
						reg = <0x0e>;
					};

					adc-chan@a {
						reg = <0x0a>;
					};

					adc-chan@8 {
						reg = <0x08>;
					};

					adc-chan@f {
						reg = <0x0f>;
					};

					adc-chan@0 {
						qcom,pre-scaling = <0x01 0x0a>;
						reg = <0x00>;
					};

					adc-chan@9 {
						reg = <0x09>;
					};
				};

				rtc@6000 {
					reg-names = "rtc\0alarm";
					interrupts = <0x00 0x61 0x01 0x01>;
					compatible = "qcom,pm8941-rtc";
					reg = <0x6000>;
				};
			};

			pmic@1 {
				#address-cells = <0x01>;
				#size-cells = <0x00>;
				compatible = "qcom,pm8916\0qcom,spmi-pmic";
				reg = <0x01 0x00>;

				audio-codec@f000 {
					vdd-cdc-tx-rx-cx-supply = <0x4d>;
					clock-names = "mclk";
					reg-names = "pmic-codec-core";
					vdd-cdc-io-supply = <0x4d>;
					vdd-micbias-supply = <0x4e>;
					interrupts = <0x01 0xf0 0x00 0x00 0x01 0xf0 0x01 0x00 0x01 0xf0 0x02 0x00 0x01 0xf0 0x03 0x00 0x01 0xf0 0x04 0x00 0x01 0xf0 0x05 0x00 0x01 0xf0 0x06 0x00 0x01 0xf0 0x07 0x00 0x01 0xf1 0x00 0x00 0x01 0xf1 0x01 0x00 0x01 0xf1 0x02 0x00 0x01 0xf1 0x03 0x00 0x01 0xf1 0x04 0x00 0x01 0xf1 0x05 0x00>;
					clocks = <0x11 0x9f>;
					interrupt-parent = <0x4c>;
					#sound-dai-cells = <0x01>;
					compatible = "qcom,pm8916-wcd-analog-codec";
					interrupt-names = "cdc_spk_cnp_int\0cdc_spk_clip_int\0cdc_spk_ocp_int\0mbhc_ins_rem_det1\0mbhc_but_rel_det\0mbhc_but_press_det\0mbhc_ins_rem_det\0mbhc_switch_int\0cdc_ear_ocp_int\0cdc_hphr_ocp_int\0cdc_hphl_ocp_det\0cdc_ear_cnp_int\0cdc_hphr_cnp_int\0cdc_hphl_cnp_int";
					reg = <0xf000>;
					phandle = <0x5f>;
				};

				pwm@bc00 {
					#pwm-cells = <0x02>;
					compatible = "qcom,pm8916-pwm";
					status = "disabled";
				};

				vibrator@c000 {
					compatible = "qcom,pm8916-vib";
					status = "disabled";
					reg = <0xc000>;
				};
			};
		};

		spi@78ba000 {
			pinctrl-names = "default\0sleep";
			#address-cells = <0x01>;
			pinctrl-0 = <0x84>;
			clock-names = "core\0iface";
			interrupts = <0x00 0x64 0x04>;
			clocks = <0x11 0x43 0x11 0x36>;
			#size-cells = <0x00>;
			dma-names = "rx\0tx";
			compatible = "qcom,spi-qup-v2.2.1";
			pinctrl-1 = <0x85>;
			status = "disabled";
			reg = <0x78ba000 0x500>;
			dmas = <0x69 0x0f 0x69 0x0e>;
		};

		dma-controller@4044000 {
			qcom,num-ees = <0x01>;
			qcom,powered-remotely;
			interrupts = <0x00 0x1d 0x04>;
			num-channels = <0x06>;
			compatible = "qcom,bam-v1.7.0";
			status = "okay";
			reg = <0x4044000 0x19000>;
			phandle = <0x57>;
			qcom,ee = <0x00>;
			#dma-cells = <0x01>;
		};

		sound@7702000 {
			pinctrl-names = "default\0sleep";
			pinctrl-0 = <0x58>;
			reg-names = "mic-iomux\0spkr-iomux";
			model = "msm8916";
			compatible = "qcom,msm8916-qdsp6-sndcard";
			pinctrl-1 = <0x59>;
			status = "disabled";
			reg = <0x7702000 0x04 0x7702004 0x04>;

			dai-link-multimedia1 {
				link-name = "MultiMedia1";

				cpu {
					sound-dai = <0x5a 0x00>;
				};
			};

			dai-link-quaternary {
				status = "disabled";
				link-name = "Quaternary MI2S";

				platform {
					sound-dai = <0x5d>;
				};

				cpu {
					sound-dai = <0x5c 0x16>;
				};
			};

			dai-link-primary {
				link-name = "Primary MI2S";

				platform {
					sound-dai = <0x5d>;
				};

				cpu {
					sound-dai = <0x5c 0x10>;
				};

				codec {
					sound-dai = <0x5e 0x00 0x5f 0x00>;
				};
			};

			dai-link-cs-voice {
				link-name = "CS-Voice";

				cpu {
					sound-dai = <0x5b 0x00>;
				};
			};

			dai-link-tertiary {
				link-name = "Tertiary MI2S";

				platform {
					sound-dai = <0x5d>;
				};

				cpu {
					sound-dai = <0x5c 0x15>;
				};

				codec {
					sound-dai = <0x5e 0x01 0x5f 0x01>;
				};
			};

			dai-link-multimedia4 {
				link-name = "MultiMedia4";

				cpu {
					sound-dai = <0x5a 0x03>;
				};
			};

			dai-link-multimedia2 {
				link-name = "MultiMedia2";

				cpu {
					sound-dai = <0x5a 0x01>;
				};
			};

			dai-link-secondary {
				status = "disabled";
				link-name = "Secondary MI2S";

				platform {
					sound-dai = <0x5d>;
				};

				cpu {
					sound-dai = <0x5c 0x12>;
				};
			};

			dai-link-multimedia3 {
				link-name = "MultiMedia3";

				cpu {
					sound-dai = <0x5a 0x02>;
				};
			};
		};

		etm@85d000 {
			clock-names = "apb_pclk\0atclk";
			clocks = <0x1f 0x08 0x1f 0x09>;
			arm,coresight-loses-context-with-cpu;
			cpu = <0x33>;
			compatible = "arm,coresight-etm4x\0arm,primecell";
			status = "disabled";
			reg = <0x85d000 0x1000>;
			phandle = <0x37>;

			out-ports {

				port {

					endpoint {
						remote-endpoint = <0x3b>;
						phandle = <0x2e>;
					};
				};
			};
		};

		audio-controller@7708000 {
			#address-cells = <0x01>;
			clock-names = "ahbix-clk\0pcnoc-mport-clk\0pcnoc-sway-clk\0mi2s-bit-clk0\0mi2s-bit-clk1\0mi2s-bit-clk2\0mi2s-bit-clk3";
			reg-names = "lpass-lpaif";
			interrupts = <0x00 0xa0 0x04>;
			clocks = <0x11 0x9a 0x11 0x96 0x11 0x97 0x11 0x9c 0x11 0x9c 0x11 0x9d 0x11 0x9e>;
			#size-cells = <0x00>;
			#sound-dai-cells = <0x01>;
			compatible = "qcom,lpass-cpu-apq8016";
			status = "okay";
			interrupt-names = "lpass-irq-lpaif";
			reg = <0x7708000 0x10000>;
		};

		syscon@1937000 {
			compatible = "qcom,tcsr-msm8916\0syscon";
			reg = <0x1937000 0x30000>;
			phandle = <0x12>;
		};

		power-manager@b0a8000 {
			compatible = "qcom,msm8916-acc";
			status = "reserved";
			reg = <0xb0a8000 0x1000>;
			phandle = <0x0c>;
		};

		cti@85b000 {
			clock-names = "apb_pclk";
			clocks = <0x1f 0x08>;
			cpu = <0x35>;
			arm,cs-dev-assoc = <0x39>;
			compatible = "arm,coresight-cti-v8-arch\0arm,coresight-cti\0arm,primecell";
			status = "disabled";
			reg = <0x85b000 0x1000>;
		};

		power-manager@b089000 {
			compatible = "qcom,msm8916-saw2-v3.0-cpu\0qcom,saw2";
			status = "reserved";
			reg = <0xb089000 0x1000>;
			phandle = <0x07>;
		};

		hwlock@1905000 {
			compatible = "qcom,tcsr-mutex";
			reg = <0x1905000 0x20000>;
			phandle = <0x1e>;
			#hwlock-cells = <0x01>;
		};

		spi@78b7000 {
			pinctrl-names = "default\0sleep";
			#address-cells = <0x01>;
			pinctrl-0 = <0x78>;
			clock-names = "core\0iface";
			interrupts = <0x00 0x61 0x04>;
			clocks = <0x11 0x3d 0x11 0x36>;
			#size-cells = <0x00>;
			dma-names = "rx\0tx";
			compatible = "qcom,spi-qup-v2.2.1";
			pinctrl-1 = <0x79>;
			status = "disabled";
			reg = <0x78b7000 0x500>;
			dmas = <0x69 0x09 0x69 0x08>;
		};

		tpiu@820000 {
			clock-names = "apb_pclk\0atclk";
			clocks = <0x1f 0x08 0x1f 0x09>;
			compatible = "arm,coresight-tpiu\0arm,primecell";
			status = "disabled";
			reg = <0x820000 0x1000>;

			in-ports {

				port {

					endpoint {
						remote-endpoint = <0x23>;
						phandle = <0x28>;
					};
				};
			};
		};

		debug@856000 {
			clock-names = "apb_pclk";
			clocks = <0x1f 0x08>;
			cpu = <0x35>;
			compatible = "arm,coresight-cpu-debug\0arm,primecell";
			status = "disabled";
			reg = <0x856000 0x1000>;
		};

		audio-codec@771c000 {
			clock-names = "ahbix-clk\0mclk";
			clocks = <0x11 0x9a 0x11 0x9f>;
			#sound-dai-cells = <0x01>;
			compatible = "qcom,msm8916-wcd-digital-codec";
			reg = <0x771c000 0x400>;
			phandle = <0x5e>;
		};

		debug@850000 {
			clock-names = "apb_pclk";
			clocks = <0x1f 0x08>;
			cpu = <0x32>;
			compatible = "arm,coresight-cpu-debug\0arm,primecell";
			status = "disabled";
			reg = <0x850000 0x1000>;
		};

		i2c@78b9000 {
			pinctrl-names = "default\0sleep";
			#address-cells = <0x01>;
			pinctrl-0 = <0x7e>;
			clock-names = "iface\0core";
			interrupts = <0x00 0x63 0x04>;
			clocks = <0x11 0x36 0x11 0x40>;
			#size-cells = <0x00>;
			compatible = "qcom,i2c-qup-v2.2.1";
			pinctrl-1 = <0x7f>;
			status = "disabled";
			reg = <0x78b9000 0x500>;
		};

		cti@858000 {
			clock-names = "apb_pclk";
			clocks = <0x1f 0x08>;
			cpu = <0x32>;
			arm,cs-dev-assoc = <0x36>;
			compatible = "arm,coresight-cti-v8-arch\0arm,coresight-cti\0arm,primecell";
			status = "disabled";
			reg = <0x858000 0x1000>;
		};

		i2c@78b6000 {
			pinctrl-names = "default\0sleep";
			#address-cells = <0x01>;
			pinctrl-0 = <0x72>;
			clock-names = "iface\0core";
			interrupts = <0x00 0x60 0x04>;
			clocks = <0x11 0x36 0x11 0x3a>;
			#size-cells = <0x00>;
			compatible = "qcom,i2c-qup-v2.2.1";
			pinctrl-1 = <0x73>;
			status = "disabled";
			reg = <0x78b6000 0x500>;
		};

		mailbox@b011000 {
			clock-names = "pll\0aux";
			clocks = <0x8f 0x11 0x01>;
			#mbox-cells = <0x01>;
			#clock-cells = <0x00>;
			compatible = "qcom,msm8916-apcs-kpss-global\0syscon";
			reg = <0xb011000 0x1000>;
			phandle = <0x03>;
		};

		thermal-sensor@4a9000 {
			nvmem-cells = <0x20 0x21>;
			#qcom,sensors = <0x05>;
			interrupts = <0x00 0xb8 0x04>;
			#thermal-sensor-cells = <0x01>;
			compatible = "qcom,msm8916-tsens\0qcom,tsens-v0_1";
			interrupt-names = "uplow";
			nvmem-cell-names = "calib\0calib_sel";
			reg = <0x4a9000 0x1000 0x4a8000 0x1000>;
			phandle = <0x90>;
		};

		qfprom@5c000 {
			#address-cells = <0x01>;
			#size-cells = <0x01>;
			compatible = "qcom,qfprom";
			reg = <0x5c000 0x1000>;

			calsel@ec {
				reg = <0xec 0x04>;
				phandle = <0x21>;
			};

			caldata@d0 {
				reg = <0xd0 0x08>;
				phandle = <0x20>;
			};
		};

		restart@4ab000 {
			compatible = "qcom,pshold";
			reg = <0x4ab000 0x04>;
		};

		memory@60000 {
			compatible = "qcom,rpm-msg-ram";
			reg = <0x60000 0x8000>;
			phandle = <0x1d>;
		};

		rng@22000 {
			clock-names = "core";
			clocks = <0x11 0x79>;
			compatible = "qcom,prng";
			reg = <0x22000 0x200>;
		};

		remoteproc@4080000 {
			power-domains = <0x50 0x00 0x50 0x03>;
			qcom,smem-state-names = "stop";
			pll-supply = <0x53>;
			clock-names = "iface\0bus\0mem\0xo";
			reg-names = "qdsp6\0rmb";
			power-domain-names = "cx\0mx";
			resets = <0x52 0x00>;
			clocks = <0x11 0x74 0x11 0xa0 0x11 0x46 0x46>;
			qcom,halt-regs = <0x12 0x18000 0x19000 0x1a000>;
			interrupts-extended = <0x01 0x00 0x18 0x01 0x4f 0x00 0x01 0x4f 0x01 0x01 0x4f 0x02 0x01 0x4f 0x03 0x01>;
			compatible = "qcom,msm8916-mss-pil\0qcom,q6v5-pil";
			status = "okay";
			interrupt-names = "wdog\0fatal\0ready\0handover\0stop-ack";
			reg = <0x4080000 0x100 0x4020000 0x40>;
			qcom,smem-states = <0x51 0x00>;
			reset-names = "mss_restart";

			bam-dmux {
				qcom,smem-state-names = "pc\0pc-ack";
				interrupts = <0x01 0x03 0x0b 0x03>;
				interrupt-parent = <0x55>;
				dma-names = "tx\0rx";
				compatible = "qcom,bam-dmux";
				status = "okay";
				interrupt-names = "pc\0pc-ack";
				dmas = <0x57 0x04 0x57 0x05>;
				qcom,smem-states = <0x56 0x01 0x56 0x0b>;
			};

			mpss {
				memory-region = <0x14>;
			};

			smd-edge {
				interrupts = <0x00 0x19 0x01>;
				qcom,smd-edge = <0x00>;
				label = "hexagon";
				qcom,remote-pid = <0x01>;
				qcom,ipc = <0x03 0x08 0x0c>;

				fastrpc {
					#address-cells = <0x01>;
					#size-cells = <0x00>;
					label = "adsp";
					compatible = "qcom,fastrpc";
					qcom,smd-channels = "fastrpcsmd-apps-dsp";

					cb@1 {
						compatible = "qcom,fastrpc-compute-cb";
						reg = <0x01>;
					};
				};

				apr {
					#address-cells = <0x01>;
					#size-cells = <0x00>;
					compatible = "qcom,apr-v2";
					qcom,apr-domain = <0x04>;
					status = "okay";
					qcom,smd-channels = "apr_audio_svc";

					apr-service@8 {
						compatible = "qcom,q6adm";
						reg = <0x08>;

						routing {
							#sound-dai-cells = <0x00>;
							compatible = "qcom,q6adm-routing";
							phandle = <0x5d>;
						};
					};

					apr-service@4 {
						compatible = "qcom,q6afe";
						reg = <0x04>;

						dais {
							#address-cells = <0x01>;
							#size-cells = <0x00>;
							#sound-dai-cells = <0x01>;
							compatible = "qcom,q6afe-dais";
							phandle = <0x5c>;

							dai@16 {
								qcom,sd-lines = <0x00 0x01>;
								reg = <0x10>;
							};

							dai@20 {
								qcom,sd-lines = <0x00 0x01>;
								reg = <0x15>;
							};
						};
					};

					apr-service@b {
						compatible = "qcom,q6cvp";
						reg = <0x0b>;
					};

					apr-service@9 {
						compatible = "qcom,q6mvm";
						reg = <0x09>;

						dais {
							#sound-dai-cells = <0x00>;
							compatible = "qcom,q6voice-dais";
							phandle = <0x5b>;
						};
					};

					apr-service@7 {
						compatible = "qcom,q6asm";
						reg = <0x07>;

						dais {
							#address-cells = <0x01>;
							#size-cells = <0x00>;
							#sound-dai-cells = <0x01>;
							compatible = "qcom,q6asm-dais";
							phandle = <0x5a>;

							dai@0 {
								direction = <0x02>;
								reg = <0x00>;
							};

							dai@3 {
								direction = <0x02>;
								reg = <0x03>;
								is-compress-dai;
							};

							dai@1 {
								direction = <0x01>;
								reg = <0x01>;
							};

							dai@2 {
								direction = <0x02>;
								reg = <0x02>;
							};
						};
					};

					apr-service@3 {
						compatible = "qcom,q6core";
						reg = <0x03>;
					};

					apr-service@a {
						compatible = "qcom,q6cvs";
						reg = <0x0a>;
					};
				};
			};

			mba {
				memory-region = <0x54>;
			};
		};

		power-manager@b0b8000 {
			compatible = "qcom,msm8916-acc";
			status = "reserved";
			reg = <0xb0b8000 0x1000>;
			phandle = <0x0f>;
		};

		replicator@824000 {
			clock-names = "apb_pclk\0atclk";
			clocks = <0x1f 0x08 0x1f 0x09>;
			compatible = "arm,coresight-dynamic-replicator\0arm,primecell";
			status = "disabled";
			reg = <0x824000 0x1000>;

			in-ports {

				port {

					endpoint {
						remote-endpoint = <0x29>;
						phandle = <0x2b>;
					};
				};
			};

			out-ports {
				#address-cells = <0x01>;
				#size-cells = <0x00>;

				port@0 {
					reg = <0x00>;

					endpoint {
						remote-endpoint = <0x27>;
						phandle = <0x2c>;
					};
				};

				port@1 {
					reg = <0x01>;

					endpoint {
						remote-endpoint = <0x28>;
						phandle = <0x23>;
					};
				};
			};
		};

		power-manager@b099000 {
			compatible = "qcom,msm8916-saw2-v3.0-cpu\0qcom,saw2";
			status = "reserved";
			reg = <0xb099000 0x1000>;
			phandle = <0x0a>;
		};

		funnel@821000 {
			clock-names = "apb_pclk\0atclk";
			clocks = <0x1f 0x08 0x1f 0x09>;
			compatible = "arm,coresight-dynamic-funnel\0arm,primecell";
			status = "disabled";
			reg = <0x821000 0x1000>;

			in-ports {
				#address-cells = <0x01>;
				#size-cells = <0x00>;

				port@7 {
					reg = <0x07>;

					endpoint {
						remote-endpoint = <0x25>;
						phandle = <0x22>;
					};
				};

				port@4 {
					reg = <0x04>;

					endpoint {
						remote-endpoint = <0x24>;
						phandle = <0x31>;
					};
				};
			};

			out-ports {

				port {

					endpoint {
						remote-endpoint = <0x26>;
						phandle = <0x2a>;
					};
				};
			};
		};

		etm@85f000 {
			clock-names = "apb_pclk\0atclk";
			clocks = <0x1f 0x08 0x1f 0x09>;
			arm,coresight-loses-context-with-cpu;
			cpu = <0x35>;
			compatible = "arm,coresight-etm4x\0arm,primecell";
			status = "disabled";
			reg = <0x85f000 0x1000>;
			phandle = <0x39>;

			out-ports {

				port {

					endpoint {
						remote-endpoint = <0x3d>;
						phandle = <0x30>;
					};
				};
			};
		};

		etm@85c000 {
			clock-names = "apb_pclk\0atclk";
			clocks = <0x1f 0x08 0x1f 0x09>;
			arm,coresight-loses-context-with-cpu;
			cpu = <0x32>;
			compatible = "arm,coresight-etm4x\0arm,primecell";
			status = "disabled";
			reg = <0x85c000 0x1000>;
			phandle = <0x36>;

			out-ports {

				port {

					endpoint {
						remote-endpoint = <0x3a>;
						phandle = <0x2d>;
					};
				};
			};
		};

		gpu@1c00000 {
			power-domains = <0x11 0x05>;
			iommus = <0x49 0x01 0x49 0x02>;
			clock-names = "core\0iface\0mem\0mem_iface\0alt_mem_iface\0gfx3d";
			reg-names = "kgsl_3d0_reg_memory";
			interrupts = <0x00 0x21 0x04>;
			clocks = <0x11 0x76 0x11 0x75 0x11 0x69 0x11 0x8e 0x11 0x8f 0x11 0x0e>;
			compatible = "qcom,adreno-306.0\0qcom,adreno";
			interrupt-names = "kgsl_3d0_irq";
			reg = <0x1c00000 0x20000>;
			operating-points-v2 = <0x48>;

			opp-table {
				compatible = "operating-points-v2";
				phandle = <0x48>;

				opp-19200000 {
					opp-hz = <0x00 0x124f800>;
				};

				opp-400000000 {
					opp-hz = <0x00 0x17d78400>;
				};
			};
		};

		serial@78af000 {
			pinctrl-names = "default\0sleep";
			pinctrl-0 = <0x6a>;
			clock-names = "core\0iface";
			interrupts = <0x00 0x6b 0x04>;
			clocks = <0x11 0x44 0x11 0x36>;
			dma-names = "rx\0tx";
			compatible = "qcom,msm-uartdm-v1.4\0qcom,msm-uartdm";
			pinctrl-1 = <0x6b>;
			status = "disabled";
			reg = <0x78af000 0x200>;
			dmas = <0x69 0x01 0x69 0x00>;
		};

		cti@85a000 {
			clock-names = "apb_pclk";
			clocks = <0x1f 0x08>;
			cpu = <0x34>;
			arm,cs-dev-assoc = <0x38>;
			compatible = "arm,coresight-cti-v8-arch\0arm,coresight-cti\0arm,primecell";
			status = "disabled";
			reg = <0x85a000 0x1000>;
		};

		interconnect@500000 {
			clock-names = "bus\0bus_a";
			clocks = <0x1f 0x02 0x1f 0x03>;
			#interconnect-cells = <0x01>;
			compatible = "qcom,msm8916-pcnoc";
			reg = <0x500000 0x11000>;
		};

		spi@78b9000 {
			pinctrl-names = "default\0sleep";
			#address-cells = <0x01>;
			pinctrl-0 = <0x80>;
			clock-names = "core\0iface";
			interrupts = <0x00 0x63 0x04>;
			clocks = <0x11 0x41 0x11 0x36>;
			#size-cells = <0x00>;
			dma-names = "rx\0tx";
			compatible = "qcom,spi-qup-v2.2.1";
			pinctrl-1 = <0x81>;
			status = "disabled";
			reg = <0x78b9000 0x500>;
			dmas = <0x69 0x0d 0x69 0x0c>;
		};

		power-manager@b088000 {
			compatible = "qcom,msm8916-acc";
			status = "reserved";
			reg = <0xb088000 0x1000>;
			phandle = <0x06>;
		};

		usb@78d9000 {
			srp-disable;
			#reset-cells = <0x01>;
			hnp-disable;
			adp-disable;
			phy-names = "usb-phy";
			clock-names = "iface\0core";
			assigned-clocks = <0x11 0x86>;
			phy_type = "ulpi";
			assigned-clock-rates = <0x4c4b400>;
			resets = <0x11 0x22>;
			interrupts = <0x00 0x86 0x04 0x00 0x8c 0x04>;
			clocks = <0x11 0x85 0x11 0x86>;
			extcon = <0x87 0x87>;
			compatible = "qcom,ci-hdrc";
			status = "okay";
			phys = <0x86>;
			reg = <0x78d9000 0x200 0x78d9200 0x200>;
			phandle = <0x88>;
			dr_mode = "otg";
			reset-names = "core";
			ahb-burst-config = <0x00>;

			ulpi {

				phy {
					v1p8-supply = <0x53>;
					clock-names = "ref\0sleep";
					resets = <0x11 0x23 0x88 0x00>;
					clocks = <0x46 0x11 0x84>;
					v3p3-supply = <0x4e>;
					extcon = <0x87>;
					#phy-cells = <0x00>;
					compatible = "qcom,usb-hs-phy-msm8916\0qcom,usb-hs-phy";
					qcom,init-seq = <0x44016b 0x2240313>;
					phandle = <0x86>;
					reset-names = "phy\0por";
				};
			};
		};

		spi@78b6000 {
			pinctrl-names = "default\0sleep";
			#address-cells = <0x01>;
			pinctrl-0 = <0x74>;
			clock-names = "core\0iface";
			interrupts = <0x00 0x60 0x04>;
			clocks = <0x11 0x3b 0x11 0x36>;
			#size-cells = <0x00>;
			dma-names = "rx\0tx";
			compatible = "qcom,spi-qup-v2.2.1";
			pinctrl-1 = <0x75>;
			status = "disabled";
			reg = <0x78b6000 0x500>;
			dmas = <0x69 0x07 0x69 0x06>;
		};

		clock@b016000 {
			#clock-cells = <0x00>;
			compatible = "qcom,msm8916-a53pll";
			reg = <0xb016000 0x40>;
			phandle = <0x8f>;
		};

		etr@826000 {
			clock-names = "apb_pclk\0atclk";
			clocks = <0x1f 0x08 0x1f 0x09>;
			compatible = "arm,coresight-tmc\0arm,primecell";
			status = "disabled";
			reg = <0x826000 0x1000>;

			in-ports {

				port {

					endpoint {
						remote-endpoint = <0x2c>;
						phandle = <0x27>;
					};
				};
			};
		};

		debug@852000 {
			clock-names = "apb_pclk";
			clocks = <0x1f 0x08>;
			cpu = <0x33>;
			compatible = "arm,coresight-cpu-debug\0arm,primecell";
			status = "disabled";
			reg = <0x852000 0x1000>;
		};

		interconnect@580000 {
			clock-names = "bus\0bus_a";
			clocks = <0x1f 0x04 0x1f 0x05>;
			#interconnect-cells = <0x01>;
			compatible = "qcom,msm8916-snoc";
			reg = <0x580000 0x14000>;
		};

		i2c@78b8000 {
			pinctrl-names = "default\0sleep";
			#address-cells = <0x01>;
			pinctrl-0 = <0x7a>;
			clock-names = "iface\0core";
			interrupts = <0x00 0x62 0x04>;
			clocks = <0x11 0x36 0x11 0x3e>;
			#size-cells = <0x00>;
			compatible = "qcom,i2c-qup-v2.2.1";
			pinctrl-1 = <0x7b>;
			status = "disabled";
			reg = <0x78b8000 0x500>;
		};

		stm@802000 {
			clock-names = "apb_pclk\0atclk";
			reg-names = "stm-base\0stm-stimulus-base";
			clocks = <0x1f 0x08 0x1f 0x09>;
			compatible = "arm,coresight-stm\0arm,primecell";
			status = "disabled";
			reg = <0x802000 0x1000 0x9280000 0x180000>;

			out-ports {

				port {

					endpoint {
						remote-endpoint = <0x22>;
						phandle = <0x25>;
					};
				};
			};
		};

		cti@811000 {
			clock-names = "apb_pclk";
			clocks = <0x1f 0x08>;
			compatible = "arm,coresight-cti\0arm,primecell";
			status = "disabled";
			reg = <0x811000 0x1000>;
		};

		i2c@78b5000 {
			pinctrl-names = "default\0sleep";
			#address-cells = <0x01>;
			pinctrl-0 = <0x6e>;
			clock-names = "iface\0core";
			interrupts = <0x00 0x5f 0x04>;
			clocks = <0x11 0x36 0x11 0x38>;
			#size-cells = <0x00>;
			compatible = "qcom,i2c-qup-v2.2.1";
			pinctrl-1 = <0x6f>;
			status = "disabled";
			reg = <0x78b5000 0x500>;
		};

		interconnect@400000 {
			clock-names = "bus\0bus_a";
			clocks = <0x1f 0x06 0x1f 0x07>;
			#interconnect-cells = <0x01>;
			compatible = "qcom,msm8916-bimc";
			reg = <0x400000 0x62000>;
		};
	};

	clocks {

		xo-board {
			#clock-cells = <0x00>;
			clock-frequency = <0x124f800>;
			compatible = "fixed-clock";
			phandle = <0x46>;
		};

		sleep-clk {
			#clock-cells = <0x00>;
			clock-frequency = <0x8000>;
			compatible = "fixed-clock";
		};
	};

	leds {
		pinctrl-names = "default";
		pinctrl-0 = <0x95>;
		compatible = "gpio-leds";

		wifi {
			linux,default-trigger = "phy0tx";
			label = "blue:wifi";
			default-state = "off";
			gpios = <0x3e 0x14 0x00>;
		};

		sim_en2 {
			label = "sim:en2";
			default-state = "off";
			gpios = <0x3e 0x03 0x00>;
		};

		os {
			linux,default-trigger = "heartbeat";
			label = "red:os";
			default-state = "on";
			gpios = <0x3e 0x16 0x00>;
		};

		sim_sel2 {
			label = "sim:sel2";
			default-state = "off";
			gpios = <0x3e 0x00 0x00>;
		};

		sim_sel {
			label = "sim:sel";
			default-state = "on";
			gpios = <0x3e 0x02 0x00>;
		};

		internet {
			label = "green:internet";
			default-state = "off";
			gpios = <0x3e 0x15 0x00>;
		};

		sim_en {
			label = "sim:en";
			default-state = "off";
			gpios = <0x3e 0x01 0x00>;
		};
	};

	psci {
		method = "smc";
		compatible = "arm,psci-1.0";

		power-domain-cpu2 {
			power-domains = <0x15>;
			domain-idle-states = <0x16>;
			#power-domain-cells = <0x00>;
			phandle = <0x0b>;
		};

		power-domain-cpu0 {
			power-domains = <0x15>;
			domain-idle-states = <0x16>;
			#power-domain-cells = <0x00>;
			phandle = <0x05>;
		};

		power-domain-cluster {
			domain-idle-states = <0x17 0x18>;
			#power-domain-cells = <0x00>;
			phandle = <0x15>;
		};

		power-domain-cpu3 {
			power-domains = <0x15>;
			domain-idle-states = <0x16>;
			#power-domain-cells = <0x00>;
			phandle = <0x0e>;
		};

		power-domain-cpu1 {
			power-domains = <0x15>;
			domain-idle-states = <0x16>;
			#power-domain-cells = <0x00>;
			phandle = <0x08>;
		};
	};

	smp2p-wcnss {
		qcom,local-pid = <0x00>;
		interrupts = <0x00 0x8f 0x01>;
		qcom,remote-pid = <0x04>;
		compatible = "qcom,smp2p";
		qcom,smem = <0x1c3 0x1af>;
		qcom,ipc = <0x03 0x08 0x12>;

		slave-kernel {
			qcom,entry-name = "slave-kernel";
			#interrupt-cells = <0x02>;
			phandle = <0x8a>;
			interrupt-controller;
		};

		master-kernel {
			qcom,entry-name = "master-kernel";
			#qcom,smem-state-cells = <0x01>;
			phandle = <0x8b>;
		};
	};

	memory@80000000 {
		device_type = "memory";
		reg = <0x00 0x80000000 0x00 0x20000000>;
	};

	memshare {
		#address-cells = <0x01>;
		#size-cells = <0x00>;
		qcom,legacy-client = <0x13>;
		compatible = "qcom,memshare";
		status = "disabled";
	};

	gpio-keys {
		pinctrl-names = "default";
		#address-cells = <0x01>;
		pinctrl-0 = <0x94>;
		autorepeat;
		#size-cells = <0x00>;
		label = "GPIO Buttons";
		compatible = "gpio-keys";

		reset {
			label = "Restart";
			linux,code = <0x198>;
			gpios = <0x3e 0x25 0x01>;
		};
	};

	timer {
		interrupts = <0x01 0x02 0xf08 0x01 0x03 0xf08 0x01 0x04 0xf08 0x01 0x01 0xf08>;
		compatible = "arm,armv8-timer";
	};

	aliases {
		sdhc2 = "/soc/sdhci@7864000";
		sdhc1 = "/soc/sdhci@7824000";
		serial0 = "/soc/serial@78b0000";
	};

	firmware {

		scm {
			#reset-cells = <0x01>;
			clock-names = "core\0bus\0iface";
			clocks = <0x11 0x68 0x11 0x67 0x11 0x66>;
			compatible = "qcom,scm-msm8916\0qcom,scm";
			phandle = <0x52>;
			qcom,dload-mode = <0x12 0x6100>;
		};
	};

	chosen {
		linux,initrd-end = <0x8265644a>;
		bootargs = "earlycon root=PARTUUID=a7ab80e8-e9d1-e8cd-f157-93f69b1d141e console=ttyMSM0,115200 no_framebuffer=true rw androidboot.emmc=true androidboot.serialno=REDACTED-SERIAL androidboot.baseband=msm mdss_mdp.panel=0:dsi:0:";
		linux,initrd-start = <0x82000000>;
		stdout-path = "serial0";
	};

	pmu {
		interrupts = <0x01 0x07 0xf04>;
		compatible = "arm,cortex-a53-pmu";
	};

	smd {
		compatible = "qcom,smd";

		rpm {
			interrupts = <0x00 0xa8 0x01>;
			qcom,smd-edge = <0x0f>;
			qcom,ipc = <0x03 0x08 0x00>;

			rpm-requests {
				compatible = "qcom,rpm-msm8916";
				qcom,smd-channels = "rpm_requests";

				clock-controller {
					#clock-cells = <0x01>;
					compatible = "qcom,rpmcc-msm8916";
					phandle = <0x1f>;
				};

				pm8916-regulators {
					vdd_l1_l2_l3-supply = <0x1a>;
					vdd_l4_l5_l6-supply = <0x1b>;
					vdd_l7-supply = <0x1b>;
					compatible = "qcom,rpm-pm8916-regulators";

					l15 {
						regulator-max-microvolt = <0x325aa0>;
						regulator-min-microvolt = <0x1b7740>;
					};

					s3 {
						regulator-max-microvolt = <0x13d620>;
						regulator-min-microvolt = <0x124f80>;
						phandle = <0x1a>;
					};

					l8 {
						regulator-max-microvolt = <0x2c4020>;
						regulator-min-microvolt = <0x2b7cd0>;
						phandle = <0x60>;
					};

					l13 {
						regulator-max-microvolt = <0x2eebb8>;
						regulator-min-microvolt = <0x2eebb8>;
						phandle = <0x4e>;
					};

					l6 {
						regulator-max-microvolt = <0x1b7740>;
						regulator-min-microvolt = <0x1b7740>;
						phandle = <0x44>;
					};

					l11 {
						regulator-max-microvolt = <0x2d0370>;
						regulator-allow-set-load;
						regulator-min-microvolt = <0x1b7740>;
						phandle = <0x67>;
						regulator-system-load = <0x30d40>;
					};

					l4 {
						regulator-max-microvolt = <0x1f47d0>;
						regulator-min-microvolt = <0x1f47d0>;
					};

					l2 {
						regulator-max-microvolt = <0x124f80>;
						regulator-min-microvolt = <0x124f80>;
						phandle = <0x43>;
					};

					l18 {
						regulator-max-microvolt = <0x2932e0>;
						regulator-min-microvolt = <0x2932e0>;
					};

					l16 {
						regulator-max-microvolt = <0x325aa0>;
						regulator-min-microvolt = <0x1b7740>;
					};

					s4 {
						regulator-max-microvolt = <0x200b20>;
						regulator-min-microvolt = <0x1b7740>;
						phandle = <0x1b>;
					};

					l9 {
						regulator-max-microvolt = <0x325aa0>;
						regulator-min-microvolt = <0x325aa0>;
						phandle = <0x8d>;
					};

					l14 {
						regulator-max-microvolt = <0x325aa0>;
						regulator-min-microvolt = <0x1b7740>;
					};

					l7 {
						regulator-max-microvolt = <0x1b7740>;
						regulator-min-microvolt = <0x1b7740>;
						phandle = <0x53>;
					};

					l12 {
						regulator-max-microvolt = <0x2d0370>;
						regulator-min-microvolt = <0x1b7740>;
						phandle = <0x68>;
					};

					l5 {
						regulator-max-microvolt = <0x1b7740>;
						regulator-min-microvolt = <0x1b7740>;
						phandle = <0x4d>;
					};

					l10 {
						regulator-max-microvolt = <0x2ab980>;
						regulator-min-microvolt = <0x2932e0>;
					};

					l1 {
						regulator-max-microvolt = <0x12b128>;
						regulator-min-microvolt = <0x12b128>;
					};

					l17 {
						regulator-max-microvolt = <0x2b7cd0>;
						regulator-always-on;
						regulator-min-microvolt = <0x2b7cd0>;
					};
				};

				power-controller {
					#power-domain-cells = <0x01>;
					compatible = "qcom,msm8916-rpmpd";
					phandle = <0x50>;
					operating-points-v2 = <0x19>;

					opp-table {
						compatible = "operating-points-v2";
						phandle = <0x19>;

						opp5 {
							opp-level = <0x05>;
						};

						opp3 {
							opp-level = <0x03>;
						};

						opp1 {
							opp-level = <0x01>;
						};

						opp6 {
							opp-level = <0x06>;
						};

						opp4 {
							opp-level = <0x04>;
						};

						opp2 {
							opp-level = <0x02>;
						};
					};
				};
			};
		};
	};

	cpus {
		#address-cells = <0x01>;
		#size-cells = <0x00>;

		cpu@1 {
			power-domains = <0x08>;
			qcom,saw = <0x0a>;
			power-domain-names = "psci";
			qcom,acc = <0x09>;
			clocks = <0x03>;
			device_type = "cpu";
			compatible = "arm,cortex-a53";
			next-level-cache = <0x02>;
			reg = <0x01>;
			enable-method = "psci";
			phandle = <0x33>;
			operating-points-v2 = <0x04>;
			#cooling-cells = <0x02>;
		};

		l2-cache {
			cache-level = <0x02>;
			compatible = "cache";
			phandle = <0x02>;
		};

		domain-idle-states {

			cluster-gdhs {
				entry-latency-us = <0x7d0>;
				exit-latency-us = <0x7d0>;
				arm,psci-suspend-param = <0x41000032>;
				compatible = "domain-idle-state";
				phandle = <0x18>;
				min-residency-us = <0x1770>;
			};

			cluster-retention {
				entry-latency-us = <0x1f4>;
				exit-latency-us = <0x1f4>;
				arm,psci-suspend-param = <0x41000012>;
				compatible = "domain-idle-state";
				phandle = <0x17>;
				min-residency-us = <0x7d0>;
			};
		};

		idle-states {
			entry-method = "psci";

			cpu-sleep-0 {
				entry-latency-us = <0x82>;
				local-timer-stop;
				idle-state-name = "standalone-power-collapse";
				exit-latency-us = <0x96>;
				arm,psci-suspend-param = <0x40000002>;
				compatible = "arm,idle-state";
				phandle = <0x16>;
				min-residency-us = <0x7d0>;
			};
		};

		cpu@2 {
			power-domains = <0x0b>;
			qcom,saw = <0x0d>;
			power-domain-names = "psci";
			qcom,acc = <0x0c>;
			clocks = <0x03>;
			device_type = "cpu";
			compatible = "arm,cortex-a53";
			next-level-cache = <0x02>;
			reg = <0x02>;
			enable-method = "psci";
			phandle = <0x34>;
			operating-points-v2 = <0x04>;
			#cooling-cells = <0x02>;
		};

		cpu@0 {
			power-domains = <0x05>;
			qcom,saw = <0x07>;
			power-domain-names = "psci";
			qcom,acc = <0x06>;
			clocks = <0x03>;
			device_type = "cpu";
			compatible = "arm,cortex-a53";
			next-level-cache = <0x02>;
			reg = <0x00>;
			enable-method = "psci";
			phandle = <0x32>;
			operating-points-v2 = <0x04>;
			#cooling-cells = <0x02>;
		};

		cpu@3 {
			power-domains = <0x0e>;
			qcom,saw = <0x10>;
			power-domain-names = "psci";
			qcom,acc = <0x0f>;
			clocks = <0x03>;
			device_type = "cpu";
			compatible = "arm,cortex-a53";
			next-level-cache = <0x02>;
			reg = <0x03>;
			enable-method = "psci";
			phandle = <0x35>;
			operating-points-v2 = <0x04>;
			#cooling-cells = <0x02>;
		};
	};

	reserved-memory {
		#address-cells = <0x02>;
		#size-cells = <0x02>;
		ranges;

		rmtfs@86700000 {
			qcom,client-id = <0x01>;
			compatible = "qcom,rmtfs-mem";
			reg = <0x00 0x86700000 0x00 0xe0000>;
			no-map;
		};

		mba@8ea00000 {
			reg = <0x00 0x8ea00000 0x00 0x100000>;
			phandle = <0x54>;
			no-map;
		};

		reserved@86680000 {
			reg = <0x00 0x86680000 0x00 0x80000>;
			no-map;
		};

		rfsa@867e0000 {
			reg = <0x00 0x867e0000 0x00 0x20000>;
			no-map;
		};

		tz@86500000 {
			reg = <0x00 0x86500000 0x00 0x180000>;
			no-map;
		};

		hypervisor@86400000 {
			reg = <0x00 0x86400000 0x00 0x100000>;
			no-map;
		};

		venus@8e500000 {
			reg = <0x00 0x8e500000 0x00 0x500000>;
			phandle = <0x4a>;
			no-map;
		};

		tz-apps@86000000 {
			reg = <0x00 0x86000000 0x00 0x300000>;
			no-map;
		};

		wcnss@8df00000 {
			reg = <0x00 0x8df00000 0x00 0x600000>;
			phandle = <0x89>;
			no-map;
		};

		smem_region@86300000 {
			reg = <0x00 0x86300000 0x00 0x100000>;
			phandle = <0x1c>;
			no-map;
		};
	};
};
